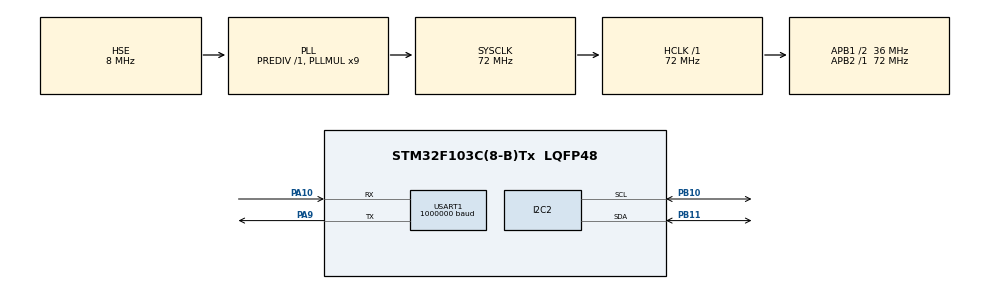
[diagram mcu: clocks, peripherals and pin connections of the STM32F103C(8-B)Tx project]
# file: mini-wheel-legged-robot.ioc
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Dma.I2C2_RX.0.Direction=DMA_PERIPH_TO_MEMORY
Dma.I2C2_RX.0.Instance=DMA1_Channel5
Dma.I2C2_RX.0.MemDataAlignment=DMA_MDATAALIGN_BYTE
Dma.I2C2_RX.0.MemInc=DMA_MINC_ENABLE
Dma.I2C2_RX.0.Mode=DMA_NORMAL
Dma.I2C2_RX.0.PeriphDataAlignment=DMA_PDATAALIGN_BYTE
Dma.I2C2_RX.0.PeriphInc=DMA_PINC_DISABLE
Dma.I2C2_RX.0.Priority=DMA_PRIORITY_HIGH
Dma.Request0=I2C2_RX
FREERTOS.Tasks01=imuTask,40,256,StartimuTask,Default,NULL,Dynamic,NULL,NULL;motorTask,24,128,StartmotorTask,Default,NULL,Dynamic,NULL,NULL;controlTask,8,512,StartcontrolTask,Default,NULL,Dynamic,NULL,NULL
FREERTOS.configTOTAL_HEAP_SIZE=10240
Mcu.Family=STM32F1
Mcu.Name=STM32F103C(8-B)Tx
Mcu.Package=LQFP48
NVIC.DMA1_Channel5_IRQn=true\:5\:0\:false\:false\:true\:true\:false\:true\:true
NVIC.PriorityGroup=NVIC_PRIORITYGROUP_4
NVIC.TIM1_UP_IRQn=true\:15\:0\:false\:false\:true\:false\:false\:true\:true
NVIC.TimeBase=TIM1_UP_IRQn
NVIC.TimeBaseIP=TIM1
NVIC.USART1_IRQn=true\:5\:0\:false\:false\:true\:true\:true\:true\:true
PA10.Mode=Asynchronous
PA10.Signal=USART1_RX
PA13.Mode=Serial_Wire
PA13.Signal=SYS_JTMS-SWDIO
PA14.Mode=Serial_Wire
PA14.Signal=SYS_JTCK-SWCLK
PA9.Mode=Asynchronous
PA9.Signal=USART1_TX
PB10.Mode=I2C
PB10.Signal=I2C2_SCL
PB11.Mode=I2C
PB11.Signal=I2C2_SDA
PD0-OSC_IN.Mode=HSE-External-Oscillator
PD0-OSC_IN.Signal=RCC_OSC_IN
PD1-OSC_OUT.Mode=HSE-External-Oscillator
PD1-OSC_OUT.Signal=RCC_OSC_OUT
ProjectManager.HeapSize=0x200
ProjectManager.StackSize=0x400
ProjectManager.TargetToolchain=CMake
RCC.AHBFreq_Value=72000000
RCC.APB1CLKDivider=RCC_HCLK_DIV2
RCC.APB1Freq_Value=36000000
RCC.APB1TimFreq_Value=72000000
RCC.APB2Freq_Value=72000000
RCC.APB2TimFreq_Value=72000000
RCC.HCLKFreq_Value=72000000
RCC.PLLMUL=RCC_PLL_MUL9
RCC.PLLSourceVirtual=RCC_PLLSOURCE_HSE
RCC.SYSCLKFreq_VALUE=72000000
RCC.SYSCLKSource=RCC_SYSCLKSOURCE_PLLCLK
RCC.USBFreq_Value=72000000
USART1.BaudRate=1000000
USART1.VirtualMode=VM_ASYNC
VP_FREERTOS_VS_CMSIS_V2.Mode=CMSIS_V2
VP_SYS_VS_tim1.Mode=TIM1
board=custom

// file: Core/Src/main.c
/* USER CODE BEGIN Header */
/**
  ******************************************************************************
  * @file           : main.c
  * @brief          : Main program body
  ******************************************************************************
  * @attention
  *
  * Copyright (c) 2026 STMicroelectronics.
  * All rights reserved.
  *
  * This software is licensed under terms that can be found in the LICENSE file
  * in the root directory of this software component.
  * If no LICENSE file comes with this software, it is provided AS-IS.
  *
  ******************************************************************************
  */
/* USER CODE END Header */
#include "main.h"
#include "cmsis_os.h"
#include "dma.h"
#include "i2c.h"
#include "usart.h"
#include "gpio.h"

void SystemClock_Config(void);
void MX_FREERTOS_Init(void);

int main(void)
{

  /* MCU Configuration--------------------------------------------------------*/

  /* Reset of all peripherals, Initializes the Flash interface and the Systick. */
  HAL_Init();

  /* Configure the system clock */
  SystemClock_Config();

  /* Initialize all configured peripherals */
  MX_GPIO_Init();
  MX_DMA_Init();
  MX_I2C2_Init();
  MX_USART1_UART_Init();

  /* Init scheduler */
  osKernelInitialize();  /* Call init function for freertos objects (in cmsis_os2.c) */
  MX_FREERTOS_Init();

  /* Start scheduler */
  osKernelStart();

  /* We should never get here as control is now taken by the scheduler */

  /* Infinite loop */
  while (1)
  {

    /* USER CODE BEGIN 3 */
    HAL_Delay(1);
  }
  /* USER CODE END 3 */
}

void SystemClock_Config(void)
{
  RCC_OscInitTypeDef RCC_OscInitStruct = {0};
  RCC_ClkInitTypeDef RCC_ClkInitStruct = {0};

  /** Initializes the RCC Oscillators according to the specified parameters
  * in the RCC_OscInitTypeDef structure.
  */
  RCC_OscInitStruct.OscillatorType = RCC_OSCILLATORTYPE_HSE;
  RCC_OscInitStruct.HSEState = RCC_HSE_ON;
  RCC_OscInitStruct.HSEPredivValue = RCC_HSE_PREDIV_DIV1;
  RCC_OscInitStruct.HSIState = RCC_HSI_ON;
  RCC_OscInitStruct.PLL.PLLState = RCC_PLL_ON;
  RCC_OscInitStruct.PLL.PLLSource = RCC_PLLSOURCE_HSE;
  RCC_OscInitStruct.PLL.PLLMUL = RCC_PLL_MUL9;
  if (HAL_RCC_OscConfig(&RCC_OscInitStruct) != HAL_OK)
  {
    Error_Handler();
  }

  /** Initializes the CPU, AHB and APB buses clocks
  */
  RCC_ClkInitStruct.ClockType = RCC_CLOCKTYPE_HCLK|RCC_CLOCKTYPE_SYSCLK
                              |RCC_CLOCKTYPE_PCLK1|RCC_CLOCKTYPE_PCLK2;
  RCC_ClkInitStruct.SYSCLKSource = RCC_SYSCLKSOURCE_PLLCLK;
  RCC_ClkInitStruct.AHBCLKDivider = RCC_SYSCLK_DIV1;
  RCC_ClkInitStruct.APB1CLKDivider = RCC_HCLK_DIV2;
  RCC_ClkInitStruct.APB2CLKDivider = RCC_HCLK_DIV1;

  if (HAL_RCC_ClockConfig(&RCC_ClkInitStruct, FLASH_LATENCY_2) != HAL_OK)
  {
    Error_Handler();
  }
}

void HAL_TIM_PeriodElapsedCallback(TIM_HandleTypeDef *htim)
{
  if (htim->Instance == TIM1)
  {
    HAL_IncTick();
  }
}

void Error_Handler(void)
{
  __disable_irq();
  while (1)
  {
  }
}

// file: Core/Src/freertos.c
/* USER CODE BEGIN Header */
/**
  ******************************************************************************
  * File Name          : freertos.c
  * Description        : Code for freertos applications
  ******************************************************************************
  * @attention
  *
  * Copyright (c) 2026 STMicroelectronics.
  * All rights reserved.
  *
  * This software is licensed under terms that can be found in the LICENSE file
  * in the root directory of this software component.
  * If no LICENSE file comes with this software, it is provided AS-IS.
  *
  ******************************************************************************
  */
/* USER CODE END Header */

#include "FreeRTOS.h"
#include "task.h"
#include "main.h"
#include "cmsis_os.h"

/* USER CODE BEGIN Includes */
#include "imu_interface.h"
/* USER CODE END Includes */

/* Definitions for imuTask */
osThreadId_t imuTaskHandle;
const osThreadAttr_t imuTask_attributes = {
  .name = "imuTask",
  .stack_size = 256 * 4,
  .priority = (osPriority_t) osPriorityHigh,
};
/* Definitions for motorTask */
osThreadId_t motorTaskHandle;
const osThreadAttr_t motorTask_attributes = {
  .name = "motorTask",
  .stack_size = 128 * 4,
  .priority = (osPriority_t) osPriorityNormal,
};
/* Definitions for controlTask */
osThreadId_t controlTaskHandle;
const osThreadAttr_t controlTask_attributes = {
  .name = "controlTask",
  .stack_size = 512 * 4,
  .priority = (osPriority_t) osPriorityLow,
};

void StartimuTask(void *argument);
void StartmotorTask(void *argument);
void StartcontrolTask(void *argument);

void MX_FREERTOS_Init(void); /* (MISRA C 2004 rule 8.1) */

void MX_FREERTOS_Init(void) {

  /* Create the thread(s) */
  /* creation of imuTask */
  imuTaskHandle = osThreadNew(StartimuTask, NULL, &imuTask_attributes);

  /* creation of motorTask */
  motorTaskHandle = osThreadNew(StartmotorTask, NULL, &motorTask_attributes);

  /* creation of controlTask */
  controlTaskHandle = osThreadNew(StartcontrolTask, NULL, &controlTask_attributes);

}

void StartimuTask(void *argument)
{
  /* USER CODE BEGIN StartimuTask */
  imu_init(IMU_GYRO_BIAS_OFFLINE);
  /* Infinite loop */
  for(;;)
  {
    float dt = 0.01f;
    imu_update(dt);
    osDelay(10);
  }
  /* USER CODE END StartimuTask */
}

void StartmotorTask(void *argument)
{
  /* USER CODE BEGIN StartmotorTask */
  /* Infinite loop */
  for(;;)
  {
    osDelay(10);
  }
  /* USER CODE END StartmotorTask */
}

void StartcontrolTask(void *argument)
{
  /* USER CODE BEGIN StartcontrolTask */
  /* Infinite loop */
  for(;;)
  {
    osDelay(5);
  }
  /* USER CODE END StartcontrolTask */
}
